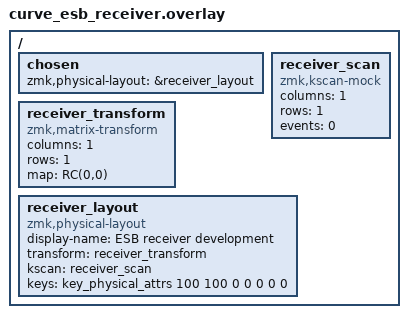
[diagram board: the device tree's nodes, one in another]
#include <dt-bindings/zmk/matrix_transform.h>
#include <physical_layouts.dtsi>
/ {
    chosen { zmk,physical-layout = &receiver_layout; };
    receiver_scan: receiver_scan {
        compatible = "zmk,kscan-mock";
        columns = <1>;
        rows = <1>;
        events = <0>;
    };
    receiver_transform: receiver_transform {
        compatible = "zmk,matrix-transform";
        columns = <1>;
        rows = <1>;
        map = <RC(0,0)>;
    };
    receiver_layout: receiver_layout {
        compatible = "zmk,physical-layout";
        display-name = "ESB receiver development";
        transform = <&receiver_transform>;
        kscan = <&receiver_scan>;
        keys = <&key_physical_attrs 100 100 0 0 0 0 0>;
    };
};
